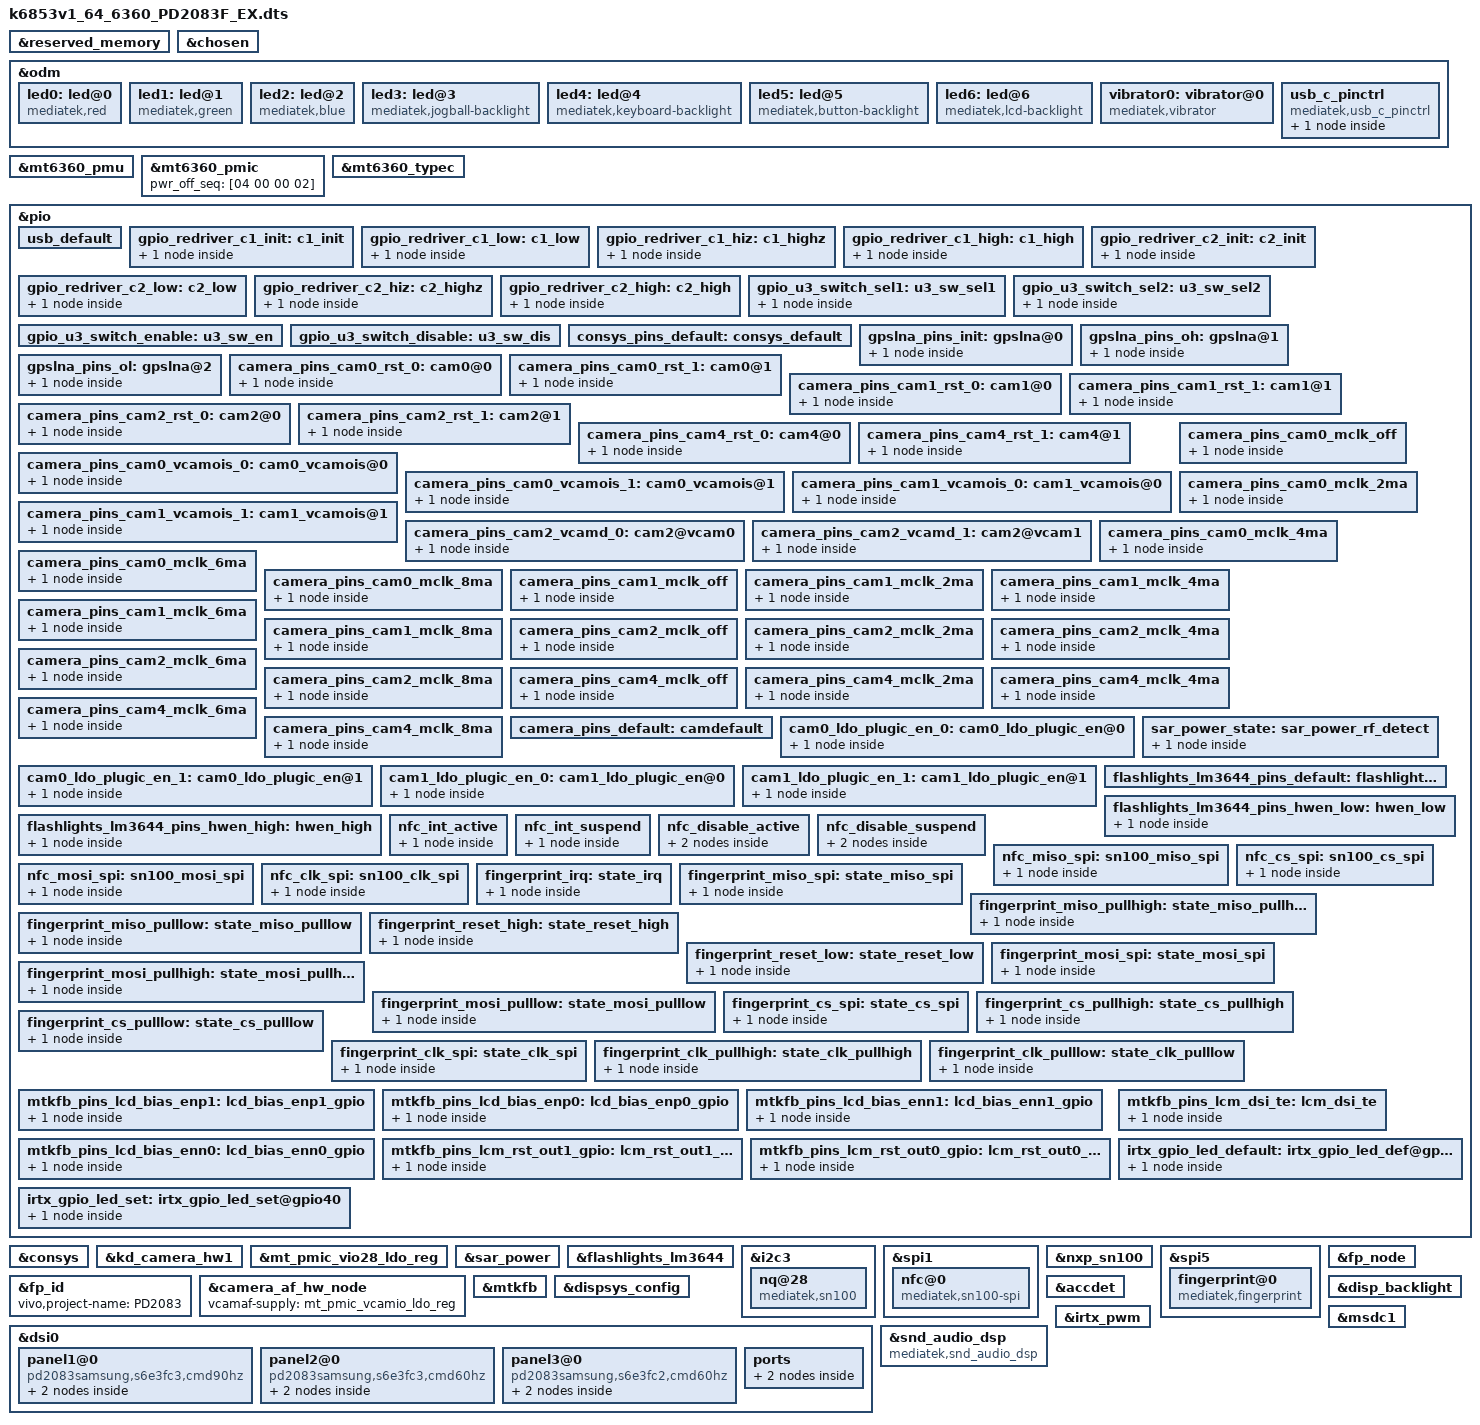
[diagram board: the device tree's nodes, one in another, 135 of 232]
/*
 * Mediatek's mt6853 SoC device tree source
 *
 * Copyright (C) 2016 MediaTek Inc.
 *
 * This program is free software; you can redistribute it and/or modify
 * it under the terms of the GNU General Public License version 2 as
 * published by the Free Software Foundation.
 *
 * This program is distributed in the hope that it will be useful,
 * but WITHOUT ANY WARRANTY; without even the implied warranty of
 * MERCHANTABILITY or FITNESS FOR A PARTICULAR PURPOSE.
 * See http://www.gnu.org/licenses/gpl-2.0.html for more details.
 */
/dts-v1/;
/plugin/;
#include <dt-bindings/interrupt-controller/irq.h>
#include <dt-bindings/interrupt-controller/arm-gic.h>
#include <dt-bindings/pinctrl/mt6853-pinfunc.h>

&reserved_memory {
};

/* chosen */
&chosen {

	atag,videolfb-fb_base_l = <0x7e605000>;
	atag,videolfb-fb_base_h = <0x0>;
	atag,videolfb-islcmfound = <1>;
	atag,videolfb-islcm_inited = <0>;
	atag,videolfb-fps= <6000>;
	atag,videolfb-vramSize= <0x1be0000>;
	atag,videolfb-lcmname=
		"nt35595_fhd_dsi_cmd_truly_nt50358_drv";
	atag,videolfb-project-name= "pd2083";
	atag,vivo-dsi-panel-type = "oled";
	atag,hbm-event-support;
	default-backlight-level = <573>;
};

&odm {
	led0:led@0 {
		compatible = "mediatek,red";
		led_mode = <0>;
		data = <1>;
		pwm_config = <0 0 0 0 0>;
	};
	led1:led@1 {
		compatible = "mediatek,green";
		led_mode = <0>;
		data = <1>;
		pwm_config = <0 0 0 0 0>;
	};
	led2:led@2 {
		compatible = "mediatek,blue";
		led_mode = <0>;
		data = <1>;
		pwm_config = <0 0 0 0 0>;
	};
	led3:led@3 {
		compatible = "mediatek,jogball-backlight";
		led_mode = <0>;
		data = <1>;
		pwm_config = <0 0 0 0 0>;
	};
	led4:led@4 {
		compatible = "mediatek,keyboard-backlight";
		led_mode = <0>;
		data = <1>;
		pwm_config = <0 0 0 0 0>;
	};
	led5:led@5 {
		compatible = "mediatek,button-backlight";
		led_mode = <0>;
		data = <1>;
		pwm_config = <0 0 0 0 0>;
	};
	led6:led@6 {
		compatible = "mediatek,lcd-backlight";
		led_mode = <4>; /*5:cpu pwm 4:lcm pwm*/
		data = <1>;
		pwm_config = <0 1 0 0 0>;
	};
	vibrator0:vibrator@0 {
		compatible = "mediatek,vibrator";
		vib_timer = <25>;
		vib_limit = <9>;
		vib_vol= <11>;
	};
	usb_c_pinctrl:usb_c_pinctrl {
		compatible = "mediatek,usb_c_pinctrl";
	};
};

&mt6360_pmu {
	mt6360,intr_gpio_num = <10>; /* direct defined GPIO num */
	mt6360,intr_gpio = <&pio 10 0x0>;
};

&mt6360_pmic {
	pwr_off_seq = [04 00 00 02];
};

&mt6360_typec {
	mt6360pd,intr_gpio_num = <9>; /* direct defined GPIO num */
	mt6360pd,intr_gpio = <&pio 9 0x0>;
	mt6360pd,pcb_gpio = <&pio 41 0x0>;
	mt6360pd,pcb_gpio_num = <41>;
};

/* USB SWITCH GPIO start */
&pio {
	usb_default: usb_default {
	};

	gpio_redriver_c1_init: c1_init {
		pins_cmd_dat {
			pinmux = <PINMUX_GPIO41__FUNC_GPIO41>;
			slew-rate = <1>;
			output-low;
		};
	};

	gpio_redriver_c1_low: c1_low {
		pins_cmd_dat {
			pinmux = <PINMUX_GPIO41__FUNC_GPIO41>;
			slew-rate = <1>;
			output-low;
		};
	};

	gpio_redriver_c1_hiz: c1_highz {
		pins_cmd_dat {
			pinmux = <PINMUX_GPIO41__FUNC_GPIO41>;
			slew-rate= <0>;
			bias-disable;
		};
	};

	gpio_redriver_c1_high: c1_high {
		pins_cmd_dat {
			pinmux = <PINMUX_GPIO41__FUNC_GPIO41>;
			slew-rate = <1>;
			output-high;
		};
	};

	gpio_redriver_c2_init: c2_init {
		pins_cmd_dat {
			pinmux = <PINMUX_GPIO40__FUNC_GPIO40>;
			slew-rate = <1>;
			output-low;
		};
	};

	gpio_redriver_c2_low: c2_low {
		pins_cmd_dat {
			pinmux = <PINMUX_GPIO40__FUNC_GPIO40>;
			slew-rate = <1>;
			output-low;
		};
	};

	gpio_redriver_c2_hiz: c2_highz {
		pins_cmd_dat {
			pinmux = <PINMUX_GPIO40__FUNC_GPIO40>;
			slew-rate= <0>;
			bias-disable;
		};
	};

	gpio_redriver_c2_high: c2_high {
		pins_cmd_dat {
			pinmux = <PINMUX_GPIO40__FUNC_GPIO40>;
			slew-rate = <1>;
			output-high;
		};
	};

	gpio_u3_switch_sel1: u3_sw_sel1 {
		pins_cmd_dat {
			pinmux = <PINMUX_GPIO11__FUNC_GPIO11>;
			slew-rate = <1>;
			output-low;
		};
	};

	gpio_u3_switch_sel2: u3_sw_sel2 {
		pins_cmd_dat {
			pinmux = <PINMUX_GPIO11__FUNC_GPIO11>;
			slew-rate = <1>;
			output-high;
		};
	};

	gpio_u3_switch_enable: u3_sw_en {
	};

	gpio_u3_switch_disable: u3_sw_dis {
	};
};

&usb_c_pinctrl {
	pinctrl-names = "usb_default",
		"redrv_c1_init",
		"redrv_c1_low",
		"redrv_c1_hiz",
		"redrv_c1_high",
		"redrv_c2_init",
		"redrv_c2_low",
		"redrv_c2_hiz",
		"redrv_c2_high",
		"switch_sel1",
		"switch_sel2",
		"switch_enable",
		"switch_disable";

	pinctrl-0 = <&usb_default>;
	pinctrl-1 = <&gpio_redriver_c1_init>;
	pinctrl-2 = <&gpio_redriver_c1_low>;
	pinctrl-3 = <&gpio_redriver_c1_hiz>;
	pinctrl-4 = <&gpio_redriver_c1_high>;
	pinctrl-5 = <&gpio_redriver_c2_init>;
	pinctrl-6 = <&gpio_redriver_c2_low>;
	pinctrl-7 = <&gpio_redriver_c2_hiz>;
	pinctrl-8 = <&gpio_redriver_c2_high>;
	pinctrl-9 = <&gpio_u3_switch_sel1>;
	pinctrl-10 = <&gpio_u3_switch_sel2>;
	pinctrl-11 = <&gpio_u3_switch_enable>;
	pinctrl-12 = <&gpio_u3_switch_disable>;
	status = "okay";

	usb_switch-data {
		en_pin_num = <0>;
		en_pin_val = <0>;
		sel_pin_num = <11>;
		sel_pin_val = <1>;
		c1_pin_num = <41>;
		c1_pin_val = <2>;
		c2_pin_num = <40>;
		c2_pin_val = <1>;
	};
};
/* USB SWITCH GPIO end */


/* CONSYS GPIO standardization */
&pio {
	consys_pins_default: consys_default {
	};
	gpslna_pins_init: gpslna@0 {
		pins_cmd_dat {
			pinmux = <PINMUX_GPIO87__FUNC_GPIO87>;
			output-low;
		};
	};
	gpslna_pins_oh: gpslna@1 {
		pins_cmd_dat {
			pinmux = <PINMUX_GPIO87__FUNC_GPS_L1_ELNA_EN>;
		};
	};
	gpslna_pins_ol: gpslna@2 {
		pins_cmd_dat {
			pinmux = <PINMUX_GPIO87__FUNC_GPIO87>;
			output-low;
		};
	};
};

&consys {
	pinctrl-names = "default", "gps_lna_state_init",
		"gps_lna_state_oh", "gps_lna_state_ol";
	pinctrl-0 = <&consys_pins_default>;
	pinctrl-1 = <&gpslna_pins_init>;
	pinctrl-2 = <&gpslna_pins_oh>;
	pinctrl-3 = <&gpslna_pins_ol>;
	status = "okay";
};
/* CONSYS end */

/* CAMERA GPIO standardization */
&pio {
	camera_pins_cam0_rst_0: cam0@0 {
		pins_cmd_dat {
			pinmux = <PINMUX_GPIO54__FUNC_GPIO54>;
			slew-rate = <1>;
			output-low;
		};
	};
	camera_pins_cam0_rst_1: cam0@1 {
		pins_cmd_dat {
			pinmux = <PINMUX_GPIO54__FUNC_GPIO54>;
			slew-rate = <1>;
			output-high;
		};
	};
	camera_pins_cam1_rst_0: cam1@0 {
		pins_cmd_dat {
			pinmux = <PINMUX_GPIO60__FUNC_GPIO60>;
			slew-rate = <1>;
			output-low;
		};
	};
	camera_pins_cam1_rst_1: cam1@1 {
		pins_cmd_dat {
			pinmux = <PINMUX_GPIO60__FUNC_GPIO60>;
			slew-rate = <1>;
			output-high;
		};
	};
	camera_pins_cam2_rst_0: cam2@0 {
		pins_cmd_dat {
			pinmux = <PINMUX_GPIO56__FUNC_GPIO56>;
			slew-rate = <1>;
			output-low;
		};
	};
	camera_pins_cam2_rst_1: cam2@1 {
		pins_cmd_dat {
			pinmux = <PINMUX_GPIO56__FUNC_GPIO56>;
			slew-rate = <1>;
			output-high;
		};
	};
	camera_pins_cam4_rst_0: cam4@0 {
		pins_cmd_dat {
			pinmux = <PINMUX_GPIO58__FUNC_GPIO58>;
			slew-rate = <1>;
			output-low;
		};
	};
	camera_pins_cam4_rst_1: cam4@1 {
		pins_cmd_dat {
			pinmux = <PINMUX_GPIO58__FUNC_GPIO58>;
			slew-rate = <1>;
			output-high;
		};
	};
	
/*main OIS power start*/
	camera_pins_cam0_vcamois_0: cam0_vcamois@0 {
		pins_cmd_dat {
			pinmux = <PINMUX_GPIO57__FUNC_GPIO57>;
			slew-rate = <1>;
			output-low;
		};
	};

	camera_pins_cam0_vcamois_1: cam0_vcamois@1 {
		pins_cmd_dat {
			pinmux = <PINMUX_GPIO57__FUNC_GPIO57>;
			slew-rate = <1>;
			output-high;
		};

	};
/*main OIS power end*/

/*sub OIS power start*/
	camera_pins_cam1_vcamois_0: cam1_vcamois@0 {
		pins_cmd_dat {
			pinmux = <PINMUX_GPIO57__FUNC_GPIO57>;
			slew-rate = <1>;
			output-low;
		};
	};

	camera_pins_cam1_vcamois_1: cam1_vcamois@1 {
		pins_cmd_dat {
			pinmux = <PINMUX_GPIO57__FUNC_GPIO57>;
			slew-rate = <1>;
			output-high;
		};

	};
/*sub OIS power end*/

/*main2 power start*/
	camera_pins_cam2_vcamd_0: cam2@vcam0 {
		pins_cmd_dat {
			pinmux = <PINMUX_GPIO114__FUNC_GPIO114>;
			slew-rate = <1>;
			output-low;
		};
	};
	camera_pins_cam2_vcamd_1: cam2@vcam1 {
		pins_cmd_dat {
			pinmux = <PINMUX_GPIO114__FUNC_GPIO114>;
			slew-rate = <1>;
			output-high;
		};
	};
/*main2 power end*/

/*main3 power start*/

/*main3 power end*/
	camera_pins_cam0_mclk_off: camera_pins_cam0_mclk_off {
		pins_cmd_dat {
			pinmux = <PINMUX_GPIO51__FUNC_GPIO51>;
			drive-strength = <1>;
		};
	};
	camera_pins_cam0_mclk_2ma: camera_pins_cam0_mclk_2ma {
		pins_cmd_dat {
			pinmux = <PINMUX_GPIO51__FUNC_CMMCLK2>;
			drive-strength = <0>;
		};
	};
	camera_pins_cam0_mclk_4ma: camera_pins_cam0_mclk_4ma {
		pins_cmd_dat {
			pinmux = <PINMUX_GPIO51__FUNC_CMMCLK2>;
			drive-strength = <1>;
		};
	};
	camera_pins_cam0_mclk_6ma: camera_pins_cam0_mclk_6ma {
		pins_cmd_dat {
			pinmux = <PINMUX_GPIO51__FUNC_CMMCLK2>;
			drive-strength = <2>;
		};
	};
	camera_pins_cam0_mclk_8ma: camera_pins_cam0_mclk_8ma {
		pins_cmd_dat {
			pinmux = <PINMUX_GPIO51__FUNC_CMMCLK2>;
			drive-strength = <3>;
		};
	};

	camera_pins_cam1_mclk_off: camera_pins_cam1_mclk_off {
		pins_cmd_dat {
			pinmux = <PINMUX_GPIO52__FUNC_GPIO52>;
			drive-strength = <1>;
		};
	};
	camera_pins_cam1_mclk_2ma: camera_pins_cam1_mclk_2ma {
		pins_cmd_dat {
			pinmux = <PINMUX_GPIO52__FUNC_CMMCLK3>;
			drive-strength = <0>;
		};
	};
	camera_pins_cam1_mclk_4ma: camera_pins_cam1_mclk_4ma {
		pins_cmd_dat {
			pinmux = <PINMUX_GPIO52__FUNC_CMMCLK3>;
			drive-strength = <1>;
		};
	};
	camera_pins_cam1_mclk_6ma: camera_pins_cam1_mclk_6ma {
		pins_cmd_dat {
			pinmux = <PINMUX_GPIO52__FUNC_CMMCLK3>;
			drive-strength = <2>;
		};
	};
	camera_pins_cam1_mclk_8ma: camera_pins_cam1_mclk_8ma {
		pins_cmd_dat {
			pinmux = <PINMUX_GPIO52__FUNC_CMMCLK3>;
			drive-strength = <3>;
		};
	};


	camera_pins_cam2_mclk_off: camera_pins_cam2_mclk_off {
		pins_cmd_dat {
			pinmux = <PINMUX_GPIO50__FUNC_GPIO50>;
			drive-strength = <1>;
		};
	};
	camera_pins_cam2_mclk_2ma: camera_pins_cam2_mclk_2ma {
		pins_cmd_dat {
			pinmux = <PINMUX_GPIO50__FUNC_CMMCLK1>;
			drive-strength = <0>;
		};
	};
	camera_pins_cam2_mclk_4ma: camera_pins_cam2_mclk_4ma {
		pins_cmd_dat {
			pinmux = <PINMUX_GPIO50__FUNC_CMMCLK1>;
			drive-strength = <1>;
		};
	};
	camera_pins_cam2_mclk_6ma: camera_pins_cam2_mclk_6ma {
		pins_cmd_dat {
			pinmux = <PINMUX_GPIO50__FUNC_CMMCLK1>;
			drive-strength = <2>;
		};
	};
	camera_pins_cam2_mclk_8ma: camera_pins_cam2_mclk_8ma {
		pins_cmd_dat {
			pinmux = <PINMUX_GPIO50__FUNC_CMMCLK1>;
			drive-strength = <3>;
		};
	};

	camera_pins_cam4_mclk_off: camera_pins_cam4_mclk_off {
		pins_cmd_dat {
			pinmux = <PINMUX_GPIO49__FUNC_GPIO49>;
			drive-strength = <1>;
		};
	};
	camera_pins_cam4_mclk_2ma: camera_pins_cam4_mclk_2ma {
		pins_cmd_dat {
			pinmux = <PINMUX_GPIO49__FUNC_CMMCLK0>;
			drive-strength = <0>;
		};
	};
	camera_pins_cam4_mclk_4ma: camera_pins_cam4_mclk_4ma {
		pins_cmd_dat {
			pinmux = <PINMUX_GPIO49__FUNC_CMMCLK0>;
			drive-strength = <1>;
		};
	};
	camera_pins_cam4_mclk_6ma: camera_pins_cam4_mclk_6ma {
		pins_cmd_dat {
			pinmux = <PINMUX_GPIO49__FUNC_CMMCLK0>;
			drive-strength = <2>;
		};
	};
	camera_pins_cam4_mclk_8ma: camera_pins_cam4_mclk_8ma {
		pins_cmd_dat {
			pinmux = <PINMUX_GPIO49__FUNC_CMMCLK0>;
			drive-strength = <3>;
		};
	};

	camera_pins_default: camdefault {
	};

	cam0_ldo_plugic_en_0: cam0_ldo_plugic_en@0 {
		pins_cmd_dat {
			pinmux = <PINMUX_GPIO37__FUNC_GPIO37>;
			slew-rate = <1>;
			output-low;
		};
	};

	cam0_ldo_plugic_en_1: cam0_ldo_plugic_en@1 {
		pins_cmd_dat {
			pinmux = <PINMUX_GPIO37__FUNC_GPIO37>;
			slew-rate = <1>;
			output-high;
		};

	};
	cam1_ldo_plugic_en_0: cam1_ldo_plugic_en@0 {
		pins_cmd_dat {
			pinmux = <PINMUX_GPIO37__FUNC_GPIO37>;
			slew-rate = <1>;
			output-low;
		};
	};

	cam1_ldo_plugic_en_1: cam1_ldo_plugic_en@1 {
		pins_cmd_dat {
			pinmux = <PINMUX_GPIO37__FUNC_GPIO37>;
			slew-rate = <1>;
			output-high;
		};

	};

};
&kd_camera_hw1 {
	pinctrl-names = "default",
			"cam0_rst0", "cam0_rst1",
			"cam1_rst0", "cam1_rst1",
			"cam2_rst0", "cam2_rst1",
			"cam4_rst0", "cam4_rst1",
			"cam0_ldo_vcamois_0", "cam0_ldo_vcamois_1",
			"cam1_ldo_vcamois_0", "cam1_ldo_vcamois_1",
			"cam2_ldo_vcamd_0", "cam2_ldo_vcamd_1",
			"cam0_mclk_off",
			"cam0_mclk_2mA", "cam0_mclk_4mA",
			"cam0_mclk_6mA", "cam0_mclk_8mA",
			"cam1_mclk_off",
			"cam1_mclk_2mA", "cam1_mclk_4mA",
			"cam1_mclk_6mA", "cam1_mclk_8mA",
			"cam2_mclk_off",
			"cam2_mclk_2mA", "cam2_mclk_4mA",
			"cam2_mclk_6mA", "cam2_mclk_8mA",
			"cam4_mclk_off",
			"cam4_mclk_2mA", "cam4_mclk_4mA",
			"cam4_mclk_6mA", "cam4_mclk_8mA",
			"cam0_ldo_plugic_en_0", "cam0_ldo_plugic_en_1",
			"cam1_ldo_plugic_en_0", "cam1_ldo_plugic_en_1";
	pinctrl-0 = <&camera_pins_default>;
	pinctrl-1 = <&camera_pins_cam0_rst_0>;
	pinctrl-2 = <&camera_pins_cam0_rst_1>;
	pinctrl-3 = <&camera_pins_cam1_rst_0>;
	pinctrl-4 = <&camera_pins_cam1_rst_1>;
	pinctrl-5 = <&camera_pins_cam2_rst_0>;
	pinctrl-6 = <&camera_pins_cam2_rst_1>;
	pinctrl-7 = <&camera_pins_cam4_rst_0>;
	pinctrl-8 = <&camera_pins_cam4_rst_1>;
	pinctrl-9 = <&camera_pins_cam0_vcamois_0>;
	pinctrl-10 = <&camera_pins_cam0_vcamois_1>;
	pinctrl-11 = <&camera_pins_cam1_vcamois_0>;
	pinctrl-12 = <&camera_pins_cam1_vcamois_1>;
	pinctrl-13 = <&camera_pins_cam2_vcamd_0>;
	pinctrl-14 = <&camera_pins_cam2_vcamd_1>;
	pinctrl-15 = <&camera_pins_cam0_mclk_off>;
	pinctrl-16 = <&camera_pins_cam0_mclk_2ma>;
	pinctrl-17 = <&camera_pins_cam0_mclk_4ma>;
	pinctrl-18 = <&camera_pins_cam0_mclk_6ma>;
	pinctrl-19 = <&camera_pins_cam0_mclk_8ma>;
	pinctrl-20 = <&camera_pins_cam1_mclk_off>;
	pinctrl-21 = <&camera_pins_cam1_mclk_2ma>;
	pinctrl-22 = <&camera_pins_cam1_mclk_4ma>;
	pinctrl-23 = <&camera_pins_cam1_mclk_6ma>;
	pinctrl-24 = <&camera_pins_cam1_mclk_8ma>;
	pinctrl-25 = <&camera_pins_cam2_mclk_off>;
	pinctrl-26 = <&camera_pins_cam2_mclk_2ma>;
	pinctrl-27 = <&camera_pins_cam2_mclk_4ma>;
	pinctrl-28 = <&camera_pins_cam2_mclk_6ma>;
	pinctrl-29 = <&camera_pins_cam2_mclk_8ma>;
	pinctrl-30 = <&camera_pins_cam4_mclk_off>;
	pinctrl-31 = <&camera_pins_cam4_mclk_2ma>;
	pinctrl-32 = <&camera_pins_cam4_mclk_4ma>;
	pinctrl-33 = <&camera_pins_cam4_mclk_6ma>;
	pinctrl-34 = <&camera_pins_cam4_mclk_8ma>;
	pinctrl-35 = <&cam0_ldo_plugic_en_0>;
	pinctrl-36 = <&cam0_ldo_plugic_en_1>;
	pinctrl-37 = <&cam1_ldo_plugic_en_0>;
	pinctrl-38 = <&cam1_ldo_plugic_en_1>;

	status = "okay";
};
/* CAMERA GPIO end */

/* add by sensor team for Psensor LED LDO1*/
&mt_pmic_vio28_ldo_reg {
	regulator-min-microvolt = <3000000>;
	regulator-max-microvolt = <3000000>;
	regulator-always-on;
};

/* ADD by vsensor team for SAR Power */
&pio {
	sar_power_state: sar_power_rf_detect {
		pins_cmd0_dat {
			pinmux = <PINMUX_GPIO1__FUNC_GPIO1>,<PINMUX_GPIO11__FUNC_GPIO11>,<PINMUX_GPIO15__FUNC_GPIO15>,<PINMUX_GPIO18__FUNC_GPIO18>,<PINMUX_GPIO19__FUNC_GPIO19>;
			slew-rate = <0>;
			bias-disable;
		};
	};
};

&sar_power {
	status="okay";
	pinctrl-names = "default";
	pinctrl-0 = <&sar_power_state>;
	sar-power-rf-detect,gpios= <&pio 1 0x0>;
	sar-power-rf-detect_1,gpios= <&pio 11 0x0>;
	sar-power-rf-detect_2,gpios= <&pio 15 0x0>;
	sar-power-rf-detect_3,gpios= <&pio 18 0x0>;
	sar-power-rf-detect_4,gpios= <&pio 19 0x0>;
};
/* ADD by vsensor team for SAR Power */

/* FLASHLIGHT START*/
&pio {
	flashlights_lm3644_pins_default: flashlight_default {
	};

	flashlights_lm3644_pins_hwen_high: hwen_high {
		pins_cmd_dat {
			pinmux = <PINMUX_GPIO138__FUNC_GPIO138>;
			slew-rate = <1>;
			output-high;
		};
	};

	flashlights_lm3644_pins_hwen_low: hwen_low {
		pins_cmd_dat {
			pinmux = <PINMUX_GPIO138__FUNC_GPIO138>;
			slew-rate = <1>;
			output-low;
		};
	};
/*
	flashlights_lm3644_pins_irq: flash_irq {
		pins_cmd_dat {
			pinmux = <PINMUX_GPIO107__FUNC_GPIO107>;
			slew-rate = <0>;
			bias-disable;
		};
	};

*/
};

&flashlights_lm3644 {
	pinctrl-names = "default", "hwen_high", "hwen_low" /*,"flash_irq"*/;
	pinctrl-0 = <&flashlights_lm3644_pins_default>;
	pinctrl-1 = <&flashlights_lm3644_pins_hwen_high>;
	pinctrl-2 = <&flashlights_lm3644_pins_hwen_low>;
	/*pinctrl-3 = <&flashlights_lm3644_pins_irq>;*/
	status = "okay";
};
/* FLASHLIGHT END*/

/* NFC start*/
&pio {
	nfc_int_active: nfc_int_active {
		pins_cmd0_dat {
			pinmux = <PINMUX_GPIO5__FUNC_GPIO5>;
			bias-pull-up;
		};
	};
	nfc_int_suspend: nfc_int_suspend {
		pins_cmd0_dat {
			pinmux = <PINMUX_GPIO5__FUNC_GPIO5>;
			bias-pull-up;
		};
	};
	nfc_disable_active: nfc_disable_active {
		pins_cmd0_dat {
			pinmux = <PINMUX_GPIO67__FUNC_GPIO67>;
			bias-pull-up;
		};
		pins_cmd1_dat {
			pinmux = <PINMUX_GPIO176__FUNC_GPIO176>;
			bias-pull-up;
		};
	};
	nfc_disable_suspend: nfc_disable_suspend {
		pins_cmd0_dat {
			pinmux = <PINMUX_GPIO67__FUNC_GPIO67>;
			bias-disable;
		};
		pins_cmd1_dat {
			pinmux = <PINMUX_GPIO176__FUNC_GPIO176>;
			bias-disable;
		};
	};

};
&i2c3 {
	status = "okay";
	#address-cells = <1>;
	#size-cells = <0>;
	clock-frequency = <400000>;
	mediatek,use-open-drain;
	nq@28 {
		compatible = "mediatek,sn100";
		reg = <0x28>;

		vivo,nfc_support = <1>;
		vivo,boardversion_shift = <4>;
		vivo,boardversion_mask = <1>;
		vivo,boardversion_num = <1>;
		vivo,boardversions = "0";

		mediatek,nq-irq = <&pio 5 0x00>;
		mediatek,nq-ven = <&pio 67 0x00>;
		mediatek,nq-firm = <&pio 176 0x00>;
		//mediatek,nq-clkreq = <&pio 81 0x00>;
		interrupt-parent = <&pio>;
		interrupts = <5 0>;
		interrupt-names = "nfc_irq";
		pinctrl-names = "nfc_active", "nfc_suspend";
		pinctrl-0 = <&nfc_int_active &nfc_disable_active>;
		pinctrl-1 = <&nfc_int_suspend &nfc_disable_suspend>;
	};
};
/* NFC end */
/* NFC SPI start */
&spi1 {
	#address-cells = <1>;
	#size-cells = <0>;
	nfc@0 {
		compatible = "mediatek,sn100-spi";
		reg = <0>;
		spi-max-frequency = <10000000>;
		status = "okay";
	};
};

&nxp_sn100 {
    status = "okay";
	pinctrl-names = "miso_spi","mosi_spi","cs_spi","clk_spi";
	pinctrl-0 = <&nfc_miso_spi>;
	pinctrl-1 = <&nfc_mosi_spi>;
	pinctrl-2 = <&nfc_cs_spi>;
	pinctrl-3 = <&nfc_clk_spi>;

};

&pio {
	nfc_miso_spi: sn100_miso_spi {
		pins_cmd_dat {
			pinmux = <PINMUX_GPIO23__FUNC_SPI1_MI>;
			drive-strength = <4>;
		};
	};
	nfc_mosi_spi: sn100_mosi_spi {
		pins_cmd_dat {
			pinmux = <PINMUX_GPIO22__FUNC_SPI1_MO>;
			drive-strength = <4>;
		};
	};
	nfc_cs_spi: sn100_cs_spi {
		pins_cmd_dat {
			pinmux = <PINMUX_GPIO21__FUNC_SPI1_CSB>;
			drive-strength = <4>;
			//bias-pull-up;
		};
	};
	nfc_clk_spi: sn100_clk_spi {
		pins_cmd_dat {
			pinmux = <PINMUX_GPIO20__FUNC_SPI1_CLK>;
			drive-strength = <4>;
		};
	};
};
/* NFC SPI end */

/* FINGERPRINT start */
&spi5 {
	#address-cells = <1>;
	#size-cells = <0>;
	fingerprint@0 {
		compatible = "mediatek,fingerprint";
		reg = <0>;
		spi-max-frequency = <8000000>;
		netlink-event = <30>;
		status = "okay";
	};
};

&fp_node {
	interrupt-parent = <&pio>;
	interrupts = <6 IRQ_TYPE_EDGE_RISING 6 0>;
	fp,vdd_use_gpio;
	fp,gpio_vdd_en= <&pio 140 0>;
	fpc,enable-wakeup;
	status = "okay";
	pinctrl-names = "fingerprint_irq", "miso_spi", "miso_pullhigh", "miso_pulllow", "reset_high", "reset_low","mosi_spi","mosi_pullhigh","mosi_pulllow","cs_spi","cs_pullhigh","cs_pulllow","clk_spi","clk_pullhigh","clk_pulllow";
	pinctrl-0 = <&fingerprint_irq>;
	pinctrl-1 = <&fingerprint_miso_spi>;
	pinctrl-2 = <&fingerprint_miso_pullhigh>;
	pinctrl-3 = <&fingerprint_miso_pulllow>;
	pinctrl-4 = <&fingerprint_reset_high>;
	pinctrl-5 = <&fingerprint_reset_low>;
	pinctrl-6 = <&fingerprint_mosi_spi>;
	pinctrl-7 = <&fingerprint_mosi_pullhigh>;
	pinctrl-8 = <&fingerprint_mosi_pulllow>;
	pinctrl-9 = <&fingerprint_cs_spi>;
	pinctrl-10 = <&fingerprint_cs_pullhigh>;
	pinctrl-11 = <&fingerprint_cs_pulllow>;
	pinctrl-12 = <&fingerprint_clk_spi>;
	pinctrl-13 = <&fingerprint_clk_pullhigh>;
	pinctrl-14 = <&fingerprint_clk_pulllow>;
};

&pio {
	fingerprint_irq: state_irq {
		pins_cmd_dat {
			pinmux = <PINMUX_GPIO6__FUNC_GPIO6>;
			slew-rate = <0>;
			bias-disable;
		};
	};

	fingerprint_miso_spi: state_miso_spi {
		pins_cmd_dat {
			pinmux = <PINMUX_GPIO31__FUNC_SPI5_MI>;
			drive-strength = <1>;
		};
	};

	fingerprint_miso_pullhigh: state_miso_pullhigh {
		pins_cmd_dat {
			pinmux = <PINMUX_GPIO31__FUNC_GPIO31>;
			slew-rate = <1>;
			output-high;
		};
	};

	fingerprint_miso_pulllow: state_miso_pulllow {
		pins_cmd_dat {
			pinmux = <PINMUX_GPIO31__FUNC_GPIO31>;
			slew-rate = <1>;
			output-low;
		};
	};

	fingerprint_reset_high: state_reset_high {
		pins_cmd_dat {
			pinmux = <PINMUX_GPIO80__FUNC_GPIO80>;
			slew-rate = <1>;
			output-high;
		};
	};

	fingerprint_reset_low: state_reset_low {
		pins_cmd_dat {
			pinmux = <PINMUX_GPIO80__FUNC_GPIO80>;
			slew-rate = <1>;
			output-low;
		};
	};

	fingerprint_mosi_spi: state_mosi_spi {
		pins_cmd_dat {
			pinmux = <PINMUX_GPIO30__FUNC_SPI5_MO>;
		};
	};
	fingerprint_mosi_pullhigh: state_mosi_pullhigh {
		pins_cmd_dat {
			pinmux = <PINMUX_GPIO30__FUNC_GPIO30>;
			slew-rate = <1>;
			drive-strength = <4>;
			output-high;
		};
	};

	fingerprint_mosi_pulllow: state_mosi_pulllow {
		pins_cmd_dat {
			pinmux = <PINMUX_GPIO30__FUNC_GPIO30>;
			slew-rate = <1>;
			output-low;
		};
	};
	fingerprint_cs_spi: state_cs_spi {
		pins_cmd_dat {
			pinmux = <PINMUX_GPIO29__FUNC_SPI5_CSB>;
			drive-strength = <1>;
		};
	};

	fingerprint_cs_pullhigh: state_cs_pullhigh {
		pins_cmd_dat {
			pinmux = <PINMUX_GPIO29__FUNC_GPIO29>;
			slew-rate = <1>;
			output-high;
		};
	};

	fingerprint_cs_pulllow: state_cs_pulllow {
		pins_cmd_dat {
			pinmux = <PINMUX_GPIO29__FUNC_GPIO29>;
			slew-rate = <1>;
			output-low;
		};
	};

	fingerprint_clk_spi: state_clk_spi {
		pins_cmd_dat {
			pinmux = <PINMUX_GPIO28__FUNC_SPI5_CLK>;
			drive-strength = <4>;
		};
	};
	fingerprint_clk_pullhigh: state_clk_pullhigh {
		pins_cmd_dat {
			pinmux = <PINMUX_GPIO28__FUNC_GPIO28>;
			slew-rate = <1>;
			output-high;
		};
	};

	fingerprint_clk_pulllow: state_clk_pulllow {
		pins_cmd_dat {
			pinmux = <PINMUX_GPIO28__FUNC_GPIO28>;
			slew-rate = <1>;
			output-low;
		};
	};
};

&fp_id {
	status="okay";
	vivo,project-name = "PD2083";
};

#include "mediatek/vivo_tp_setting/mtk-vivo-tp-PD2083F_EX.dtsi"
/*#include "mediatek/cust_mt6853_camera.dtsi"*/
/*#include <k6853v1_64_6360/cust.dtsi> */
#include "mediatek/cust_vivo_PD2083F_EX.dtsi"
/* DISPSYS GPIO standardization */

#ifndef CONFIG_FPGA_EARLY_PORTING
&pio {
	mtkfb_pins_lcd_bias_enp1: lcd_bias_enp1_gpio {
		pins_cmd_dat {
			pinmux = <PINMUX_GPIO137__FUNC_GPIO137>;
			slew-rate = <1>;
			output-high;
		};
	};

	mtkfb_pins_lcd_bias_enp0: lcd_bias_enp0_gpio {
		pins_cmd_dat {
			pinmux = <PINMUX_GPIO137__FUNC_GPIO137>;
			slew-rate = <1>;
			output-low;
		};
	};

	mtkfb_pins_lcd_bias_enn1: lcd_bias_enn1_gpio {
		pins_cmd_dat {
			pinmux = <PINMUX_GPIO138__FUNC_GPIO138>;
			slew-rate = <1>;
			output-high;
		};
	};

	mtkfb_pins_lcd_bias_enn0: lcd_bias_enn0_gpio {
		pins_cmd_dat {
			pinmux = <PINMUX_GPIO138__FUNC_GPIO138>;
			slew-rate = <1>;
			output-low;
		};
	};

	mtkfb_pins_lcm_rst_out1_gpio: lcm_rst_out1_gpio {
		pins_cmd_dat {
			pinmux = <PINMUX_GPIO86__FUNC_GPIO86>;
			slew-rate = <1>;
			output-high;
		};
	};

	mtkfb_pins_lcm_rst_out0_gpio: lcm_rst_out0_gpio {
		pins_cmd_dat {
			pinmux = <PINMUX_GPIO86__FUNC_GPIO86>;
			slew-rate = <1>;
			output-low;
		};
	};
	mtkfb_pins_lcm_dsi_te: lcm_dsi_te {
		pins_cmd_dat {
			pinmux = <PINMUX_GPIO84__FUNC_DSI_TE>;
		};
	};
};

&camera_af_hw_node {
	vcamaf-supply = <&mt_pmic_vcamio_ldo_reg>;
	status = "okay";
};

&mtkfb {
	pinctrl-names = "lcd_bias_enp1_gpio", "lcd_bias_enp0_gpio",
		"lcd_bias_enn1_gpio", "lcd_bias_enn0_gpio",
		"lcm_rst_out1_gpio", "lcm_rst_out0_gpio",
		"mode_te_te";
	pinctrl-0 = <&mtkfb_pins_lcd_bias_enp1>;
	pinctrl-1 = <&mtkfb_pins_lcd_bias_enp0>;
	pinctrl-2 = <&mtkfb_pins_lcd_bias_enn1>;
	pinctrl-3 = <&mtkfb_pins_lcd_bias_enn0>;
	pinctrl-4 = <&mtkfb_pins_lcm_rst_out1_gpio>;
	pinctrl-5 = <&mtkfb_pins_lcm_rst_out0_gpio>;
	pinctrl-6 = <&mtkfb_pins_lcm_dsi_te>;
	status = "okay";
};
&dispsys_config {
	pinctrl-names =
		"lcm_rst_out1_gpio", "lcm_rst_out0_gpio",
		"mode_te_te";
	pinctrl-0 = <&mtkfb_pins_lcm_rst_out1_gpio>;
	pinctrl-1 = <&mtkfb_pins_lcm_rst_out0_gpio>;
	pinctrl-2 = <&mtkfb_pins_lcm_dsi_te>;
	status = "okay";
};

&dispsys_config {
	pinctrl-names =
	"lcm_rst_out1_gpio", "lcm_rst_out0_gpio",
		"mode_te_te";
	pinctrl-0 = <&mtkfb_pins_lcm_rst_out1_gpio>;
	pinctrl-1 = <&mtkfb_pins_lcm_rst_out0_gpio>;
	pinctrl-2 = <&mtkfb_pins_lcm_dsi_te>;

	helper-name = "MTK_DRM_OPT_STAGE",
		"MTK_DRM_OPT_USE_CMDQ",
		"MTK_DRM_OPT_USE_M4U",
		"MTK_DRM_OPT_SODI_SUPPORT",
		"MTK_DRM_OPT_IDLE_MGR",
		"MTK_DRM_OPT_IDLEMGR_SWTCH_DECOUPLE",
		"MTK_DRM_OPT_IDLEMGR_BY_REPAINT",
		"MTK_DRM_OPT_IDLEMGR_ENTER_ULPS",
		"MTK_DRM_OPT_IDLEMGR_KEEP_LP11",
		"MTK_DRM_OPT_DYNAMIC_RDMA_GOLDEN_SETTING",
		"MTK_DRM_OPT_IDLEMGR_DISABLE_ROUTINE_IRQ",
		"MTK_DRM_OPT_MET_LOG",
		"MTK_DRM_OPT_USE_PQ",
		"MTK_DRM_OPT_ESD_CHECK_RECOVERY",
		"MTK_DRM_OPT_ESD_CHECK_SWITCH",
		"MTK_DRM_OPT_PRESENT_FENCE",
		"MTK_DRM_OPT_RDMA_UNDERFLOW_AEE",
		"MTK_DRM_OPT_DSI_UNDERRUN_AEE",
		"MTK_DRM_OPT_HRT",
		"MTK_DRM_OPT_HRT_MODE",
		"MTK_DRM_OPT_DELAYED_TRIGGER",
		"MTK_DRM_OPT_OVL_EXT_LAYER",
		"MTK_DRM_OPT_AOD",
		"MTK_DRM_OPT_RPO",
		"MTK_DRM_OPT_DUAL_PIPE",
		"MTK_DRM_OPT_DC_BY_HRT",
		"MTK_DRM_OPT_OVL_WCG",
		"MTK_DRM_OPT_OVL_SBCH",
		"MTK_DRM_OPT_COMMIT_NO_WAIT_VBLANK",
		"MTK_DRM_OPT_MET",
		"MTK_DRM_OPT_REG_PARSER_RAW_DUMP",
		"MTK_DRM_OPT_VP_PQ",
		"MTK_DRM_OPT_GAME_PQ",
		"MTK_DRM_OPT_MMPATH",
		"MTK_DRM_OPT_HBM",
		"MTK_DRM_OPT_VDS_PATH_SWITCH",
		"MTK_DRM_OPT_LAYER_REC",
		"MTK_DRM_OPT_CLEAR_LAYER";

	helper-value = <0>, /*MTK_DRM_OPT_STAGE*/
		<1>, /*MTK_DRM_OPT_USE_CMDQ*/
		<1>, /*MTK_DRM_OPT_USE_M4U*/
		<0>, /*MTK_DRM_OPT_SODI_SUPPORT*/
		<1>, /*MTK_DRM_OPT_IDLE_MGR*/
		<0>, /*MTK_DRM_OPT_IDLEMGR_SWTCH_DECOUPLE*/
		<1>, /*MTK_DRM_OPT_IDLEMGR_BY_REPAINT*/
		<0>, /*MTK_DRM_OPT_IDLEMGR_ENTER_ULPS*/
		<0>, /*MTK_DRM_OPT_IDLEMGR_KEEP_LP11*/
		<0>, /*MTK_DRM_OPT_DYNAMIC_RDMA_GOLDEN_SETTING*/
		<1>, /*MTK_DRM_OPT_IDLEMGR_DISABLE_ROUTINE_IRQ*/
		<0>, /*MTK_DRM_OPT_MET_LOG*/
		<1>, /*MTK_DRM_OPT_USE_PQ*/
		<1>, /*MTK_DRM_OPT_ESD_CHECK_RECOVERY*/
		<1>, /*MTK_DRM_OPT_ESD_CHECK_SWITCH*/
		<1>, /*MTK_DRM_OPT_PRESENT_FENCE*/
		<0>, /*MTK_DRM_OPT_RDMA_UNDERFLOW_AEE*/
		<1>, /*MTK_DRM_OPT_DSI_UNDERRUN_AEE*/
		<1>, /*MTK_DRM_OPT_HRT*/
		<1>, /*MTK_DRM_OPT_HRT_MODE*/
		<0>, /*MTK_DRM_OPT_DELAYED_TRIGGER*/
		<1>, /*MTK_DRM_OPT_OVL_EXT_LAYER*/
		<1>, /*MTK_DRM_OPT_AOD*/
		<1>, /*MTK_DRM_OPT_RPO*/
		<0>, /*MTK_DRM_OPT_DUAL_PIPE*/
		<0>, /*MTK_DRM_OPT_DC_BY_HRT*/
		<0>, /*MTK_DRM_OPT_OVL_WCG*/
		<0>, /*MTK_DRM_OPT_OVL_SBCH*/
		<1>, /*MTK_DRM_OPT_COMMIT_NO_WAIT_VBLANK*/
		<0>, /*MTK_DRM_OPT_MET*/
		<0>, /*MTK_DRM_OPT_REG_PARSER_RAW_DUMP*/
		<0>, /*MTK_DRM_OPT_VP_PQ*/
		<0>, /*MTK_DRM_OPT_GAME_PQ*/
		<0>, /*MTK_DRM_OPT_MMPATH*/
		<1>, /*MTK_DRM_OPT_HBM*/
		<1>, /*MTK_DRM_OPT_VDS_PATH_SWITCH*/
		<0>, /*MTK_DRM_OPT_LAYER_REC*/
		<1>; /*MTK_DRM_OPT_CLEAR_LAYER*/
};

&disp_backlight {
	max-brightness = <2047>;
	led-bits = <11>;
	default-state = "on";
};

&dsi0 {
	status = "okay";
	#address-cells = <1>;
	#size-cells = <0>;
	panel1@0 {
		compatible = "pd2083samsung,s6e3fc3,cmd90hz";
		reg = <0>;
		lcm_vci-supply = <&mt_pmic_vfp_ldo_reg>;
		pm-enable-gpios = <&pio 41 0>;
		vddi_en-gpios = <&pio 137 0>;
		reset-gpios = <&pio 86 0>;
		vddr_en-gpios = <&pio 131 0>;
		err_flag-gpios = <&pio 71 0>;
		elvdd_ctrl-gpios = <&pio 132 0>;
		pinctrl-names = "default";
		port {
			panel_in1: endpoint {
				remote-endpoint = <&dsi_out>;
			};
		};
	};
	panel2@0 {
		compatible = "pd2083samsung,s6e3fc3,cmd60hz";
		reg = <1>;
		lcm_vci-supply = <&mt_pmic_vfp_ldo_reg>;
		pm-enable-gpios = <&pio 41 0>;
		vddi_en-gpios = <&pio 137 0>;
		reset-gpios = <&pio 86 0>;
		vddr_en-gpios = <&pio 131 0>;
		err_flag-gpios = <&pio 71 0>;
		elvdd_ctrl-gpios = <&pio 132 0>;
		pinctrl-names = "default";
		port {
			panel_in2: endpoint {
				remote-endpoint = <&dsi_out>;
			};
		};
	};
	panel3@0 {
		compatible = "pd2083samsung,s6e3fc2,cmd60hz";
		reg = <1>;
		lcm_vci-supply = <&mt_pmic_vfp_ldo_reg>;
		pm-enable-gpios = <&pio 41 0>;
		vddi_en-gpios = <&pio 137 0>;
		reset-gpios = <&pio 86 0>;
		vddr_en-gpios = <&pio 131 0>;
		err_flag-gpios = <&pio 71 0>;
		elvdd_ctrl-gpios = <&pio 132 0>;
		pinctrl-names = "default";
		port {
			panel_in3: endpoint {
				remote-endpoint = <&dsi_out>;
			};
		};
	};
	ports {
		port {
			dsi_out: endpoint {
				remote-endpoint = <&panel_in1>;
			};
		};
	};
};

/* accdet start */
&accdet {
	/* accdet micbias voltage: 0x09:2.85v 0x08:2.8v 0x07,
	 * 2.7v;0x05,2.5v;0x02,1.9v
	 */
	accdet-mic-vol = <7>;
	/* accdet pwm_width, pwm_thresh, fall_delay, rise_delay
	 * debounce0, debounce1, debounce3, debounce4
	 * eint pwm_width, eint pwm_thresh
	 * eint deb(debounce0, debounce1, debounce2, debounce3), inv_debounce
	 */
	headset-mode-setting = <0x500 0x500 1 0x1f0
				0x800 0x800 0x2000 0x44
				0x4 0x1
				0x5 0x3 0x3 0x5 0xe>;
	accdet-plugout-debounce = <16>;
	/*1:ACC mode, 2:low cost without in bias, 6:low cost with in bias*/
	accdet-mic-mode = <2>;
	/*0--MD_MAX--UP_MAX--DW_MAX*/
	headset-three-key-threshold = <0 90 210 430>;
	headset-three-key-threshold-CDD = <0 121 192 600>;
	/*0--MD_MAX--VOICE_MAX--UP_MAX--DW_MAX*/
	headset-four-key-threshold = <0 50 96 210 430>;

	/* select VTH to 2v and 500k, use internal resitance */
	eint_use_ext_res = <0>;
	status = "okay";
};
/* accdet end */


/* feature : $enable $dl_mem $ul_mem $ref_mem */
&snd_audio_dsp {
	compatible = "mediatek,snd_audio_dsp";
	mtk_dsp_voip = <0x1f 0xffffffff 0xffffffff 0xffffffff 0x30000>;
	mtk_dsp_primary = <0x5 0xffffffff 0xffffffff 0xffffffff 0x30000>;
	mtk_dsp_offload = <0x0 0xffffffff 0xffffffff 0xffffffff 0x400000>;
	mtk_dsp_deep = <0x5 0xffffffff 0xffffffff 0xffffffff 0x30000>;
	mtk_dsp_playback = <0x1 0x4 0xffffffff 0x14 0x30000>;
	mtk_dsp_music = <0x1 0xffffffff 0xffffffff 0xffffffff 0x0>;
	mtk_dsp_capture1 = <0x1 0xffffffff 0xd 0x13 0x20000>;
	mtk_dsp_a2dp = <0x0 0xffffffff 0xffffffff 0xffffffff 0x40000>;
	mtk_dsp_dataprovider = <0x0 0xffffffff 0xf 0xffffffff 0x30000>;
	mtk_dsp_call_final = <0x5 0x0 0x10 0x14 0x18000>;
	mtk_dsp_fast = <0x5 0xffffffff 0xffffffff 0xffffffff 0x5000>;
	mtk_dsp_ktv = <0x0 0x8 0x12 0xffffffff 0x10000>;
	mtk_dsp_capture_raw = <0x0 0xffffffff 0xffffffff 0xffffffff 0x20000>;
	mtk_dsp_ver = <0x1>;
	swdsp_smartpa_process_enable = <0x5>;
	mtk_dsp_mem_afe = <0x1 0x40000>; /* always enable */
};

/* IRTX GPIO Start */
&irtx_pwm {
	pinctrl-names = "irtx_gpio_led_default", "irtx_gpio_led_set";
	pinctrl-0 = <&irtx_gpio_led_default>;
	pinctrl-1 = <&irtx_gpio_led_set>;
	status = "okay";
};
&pio {
	/* IRTX GPIO Settings -Start */
	/* default: GPIO0, output, high */
	irtx_gpio_led_default:irtx_gpio_led_def@gpio40 {
		pins_cmd_dat {
		};
	};

	irtx_gpio_led_set:irtx_gpio_led_set@gpio40 {
		pins_cmd_dat {
		};
	};
}; /* IRTX GPIO Settings -End */

#endif

&msdc1 {
	fast_power_off;
	PD2083F_EX;
};

/*End of this file, DO NOT ADD ANYTHING HERE*/

